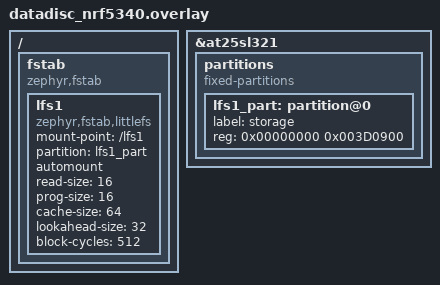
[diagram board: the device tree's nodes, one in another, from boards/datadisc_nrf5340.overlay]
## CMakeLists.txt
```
#
# Copyright (c) 2020-2022 Griffin Adams
#
# SPDX-License-Identifier: Apache-2.0
#

cmake_minimum_required(VERSION 3.20.4)

set(ZEPHYR_EXTRA_MODULES ${CMAKE_CURRENT_LIST_DIR}/drivers/kx134 ${CMAKE_CURRENT_LIST_DIR}/drivers/bm1422)
set(CONF_FILE ${CMAKE_CURRENT_LIST_DIR}/prj.conf)
list(APPEND CONF_FILE ${CMAKE_CURRENT_LIST_DIR}/kx134.conf)
list(APPEND CONF_FILE ${CMAKE_CURRENT_LIST_DIR}/bm1422.conf)
#set(DTC_OVERLAY_FILE ${CMAKE_CURRENT_LIST_DIR}/boards/datadisc_nrf5340_cpuapp.overlay)

find_package(Zephyr REQUIRED HINTS $ENV{ZEPHYR_BASE})
project(datadisc)

# Point to DataDisc root directory.
set(DATADISC_DIR ${CMAKE_CURRENT_LIST_DIR} CACHE PATH "DataDisc root directory")

FILE(GLOB app_sources src/*.c)
target_sources(app PRIVATE ${app_sources})

zephyr_library_include_directories(include)
```

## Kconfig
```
# Copyright (c) 2019-2020 Nordic Semiconductor ASA
# SPDX-License-Identifier: Apache-2.0

config APP_WIPE_STORAGE
	bool "Option to clear the flash area before mounting"
	help
	  Use this to force an existing file system to be created.

choice
	prompt "Storage and file system type used by the application"
	default APP_MSC_STORAGE_NONE
	help
	  Specify the type of storage and file system.

config APP_MSC_STORAGE_NONE
	bool "Use RAM disk as block device"
	imply DISK_DRIVER_RAM

config APP_MSC_STORAGE_RAM
	bool "Use RAM disk and FAT file system"
	imply DISK_DRIVER_RAM
	imply FILE_SYSTEM
	imply FAT_FILESYSTEM_ELM

config APP_MSC_STORAGE_FLASH_FATFS
	bool "Use FLASH disk and FAT file system"
	imply DISK_DRIVER_FLASH
	imply FILE_SYSTEM
	imply FAT_FILESYSTEM_ELM

config APP_MSC_STORAGE_FLASH_LITTLEFS
	bool "Use FLASH disk and LittleFS"
	imply DISK_DRIVER_FLASH
	imply FILE_SYSTEM
	imply FILE_SYSTEM_LITTLEFS

config APP_MSC_STORAGE_SDCARD
	bool "Use SDHC and FAT file system"
	imply DISK_DRIVER_SDMMC
	imply FILE_SYSTEM
	imply FAT_FILESYSTEM_ELM

endchoice

config DISK_RAM_VOLUME_SIZE
	default 32 if APP_MSC_STORAGE_NONE

config MASS_STORAGE_DISK_NAME
	default "NAND" if DISK_DRIVER_FLASH
	default "RAM" if DISK_DRIVER_RAM
	default "SD" if DISK_DRIVER_SDMMC

if DISK_DRIVER_FLASH

config FLASH_MAP
	default y

config FLASH_PAGE_LAYOUT
	default y

config DISK_FLASH_START
	default 0x0

config FLASH_LOG_LEVEL
	default 3

DT_COMPAT_QSPI_NOR := nordic,qspi-nor

config NORDIC_QSPI_NOR
	default $(dt_compat_enabled,$(DT_COMPAT_QSPI_NOR))

if NORDIC_QSPI_NOR

config NORDIC_QSPI_NOR_FLASH_LAYOUT_PAGE_SIZE
	default 4096

config DISK_FLASH_DEV_NAME
	default "MX25R64" if "$(dt_nodelabel_enabled,mx25r64)"
	default "GD25Q16" if "$(dt_nodelabel_enabled,gd25q16)"

config DISK_VOLUME_SIZE
	default 0x20000

config DISK_FLASH_MAX_RW_SIZE
	default 4096

config DISK_FLASH_ERASE_ALIGNMENT
	default 0x1000

config DISK_ERASE_BLOCK_SIZE
	default 0x1000

endif # NORDIC_QSPI_NOR

endif # DISK_DRIVER_FLASH

source "Kconfig.zephyr"
```

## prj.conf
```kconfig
# Enable mcumgr.
CONFIG_MCUMGR=y

# Enable most core commands.
CONFIG_MCUMGR_CMD_IMG_MGMT=y
CONFIG_MCUMGR_CMD_OS_MGMT=y

# Ensure an MCUboot-compatible binary is generated.
CONFIG_BOOTLOADER_MCUBOOT=y
CONFIG_PM_EXTERNAL_FLASH_MCUBOOT_SECONDARY=n

# enable console
CONFIG_USE_SEGGER_RTT=y
CONFIG_RTT_CONSOLE=y
CONFIG_UART_CONSOLE=n

# logging
CONFIG_LOG=y
CONFIG_LOG_PRINTK=y
CONFIG_LOG_BACKEND_RTT=y
CONFIG_LOG_DEFAULT_LEVEL=3
CONFIG_EXTRA_EXCEPTION_INFO=y

CONFIG_CPU_LOAD=y
CONFIG_CPU_LOAD_LOG_LEVEL_INF=y
CONFIG_CPU_LOAD_LOG_PERIODIC=y

# Enable the UART driver
CONFIG_UART_ASYNC_API=y
CONFIG_NRFX_UARTE0=y
CONFIG_SERIAL=y

# Bluetooth
CONFIG_BT=y
CONFIG_BT_SMP=y
CONFIG_BT_PERIPHERAL=y
CONFIG_BT_DEVICE_NAME="DataDisc v2"
CONFIG_BT_DEVICE_APPEARANCE=1345
CONFIG_BT_MAX_CONN=2
CONFIG_BT_MAX_PAIRED=2
CONFIG_BT_BAS=y

# Enable the NUS service
CONFIG_BT_NUS=y

# Allow for large Bluetooth data packets.
CONFIG_BT_L2CAP_TX_MTU=252
CONFIG_BT_BUF_ACL_RX_SIZE=256

# Enable the Bluetooth (unauthenticated) and shell mcumgr transports.
CONFIG_MCUMGR_SMP_BT=y
CONFIG_MCUMGR_SMP_BT_AUTHEN=n

# Some command handlers require a large stack.
CONFIG_SYSTEM_WORKQUEUE_STACK_SIZE=4092

# File System
# Optionally force the file system to be recreated
#CONFIG_APP_WIPE_STORAGE=y

# fs_dirent structures are big.
CONFIG_MAIN_STACK_SIZE=2048

# Let __ASSERT do its job
CONFIG_DEBUG=y

CONFIG_FLASH=y
CONFIG_FLASH_MAP=y
CONFIG_FLASH_PAGE_LAYOUT=y

# Nordic specific external flash stuff
#CONFIG_PM_EXTERNAL_FLASH=y
#CONFIG_PM_EXTERNAL_FLASH_DEV_NAME="AT25SL321"
CONFIG_PM_EXTERNAL_FLASH_BASE=0x0
#CONFIG_PM_EXTERNAL_FLASH_SIZE=0x00400000

CONFIG_FILE_SYSTEM=y
CONFIG_FAT_FILESYSTEM_ELM=y
#CONFIG_FS_FATFS_EXFAT=y

CONFIG_MPU_ALLOW_FLASH_WRITE=y

# USB related configs
CONFIG_USB_DEVICE_STACK=y
CONFIG_USB_DEVICE_PRODUCT="DataDisc"
CONFIG_USB_DRIVER_LOG_LEVEL_ERR=y
CONFIG_USB_MASS_STORAGE=y
CONFIG_USB_DEVICE_LOG_LEVEL_ERR=y
CONFIG_USB_MASS_STORAGE_LOG_LEVEL_ERR=y
#CONFIG_USB_CDC_ACM=y

CONFIG_APP_MSC_STORAGE_FLASH_FATFS=y

CONFIG_DISK_DRIVER_FLASH=y
CONFIG_DISK_FLASH_DEV_NAME="MX25U32"
#CONFIG_DISK_FLASH_DEV_NAME="AT25SL321"
CONFIG_DISK_VOLUME_SIZE=0x00400000


# Shell
CONFIG_PRINTK=y
#CONFIG_SHELL=y
#CONFIG_SHELL_MINIMAL=y
#CONFIG_SHELL_STACK_SIZE=1024
#CONFIG_SHELL_BACKEND_SERIAL=y

#CONFIG_THREAD_MONITOR=y
#CONFIG_INIT_STACKS=y
#CONFIG_BOOT_BANNER=n
#CONFIG_THREAD_NAME=y
#CONFIG_LOG=n
#CONFIG_CBPRINTF_NANO=y

#CONFIG_SHELL_BACKEND_SERIAL_CHECK_DTR=y
#CONFIG_UART_LINE_CTRL=y
#CONFIG_SHELL_BACKEND_SERIAL_INIT_PRIORITY=51

CONFIG_REBOOT=y

# Drivers
CONFIG_SENSOR=y

CONFIG_NFCT_PINS_AS_GPIOS=y

CONFIG_SPI=y
CONFIG_I2C=y
CONFIG_PWM=y
CONFIG_ADC=y

CONFIG_NEWLIB_LIBC=y

# Enable bonding
CONFIG_NVS=y
CONFIG_SETTINGS=y
CONFIG_BT_SETTINGS=n

CONFIG_ASSERT=y
```

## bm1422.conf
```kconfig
#
# bm1422 (C:/Users/Griffin/Desktop/Workspace/datadisc/drivers/bm1422)
#
CONFIG_BM1422=y
# CONFIG_BM1422_LOG_LEVEL_OFF is not set
# CONFIG_BM1422_LOG_LEVEL_ERR is not set
# CONFIG_BM1422_LOG_LEVEL_WRN is not set
CONFIG_BM1422_LOG_LEVEL_INF=y
# CONFIG_BM1422_LOG_LEVEL_DBG is not set
CONFIG_BM1422_12_BIT=y
# CONFIG_BM1422_14_BIT=y
# CONFIG_BM1422_AVC_NONE is not set
CONFIG_BM1422_AVC_2SAMPLES=y
# CONFIG_BM1422_AVC_4SAMPLES=y
# CONFIG_BM1422_AVC_8SAMPLES is not set
# CONFIG_BM1422_AVC_16SAMPLES is not set
# CONFIG_BM1422_ODR_10HZ is not set
# CONFIG_BM1422_ODR_20HZ is not set
# CONFIG_BM1422_ODR_100HZ=y
CONFIG_BM1422_ODR_1KHZ=y
CONFIG_BM1422_DREN=y
CONFIG_BM1422_DRP=y
# CONFIG_BM1422_TRIGGER_NONE is not set
# CONFIG_BM1422_TRIGGER_GLOBAL_THREAD is not set
CONFIG_BM1422_TRIGGER_OWN_THREAD=y
CONFIG_BM1422_THREAD_PRIORITY=10
CONFIG_BM1422_THREAD_STACK_SIZE=1024
# end of bm1422 (C:/Users/Griffin/Desktop/Workspace/datadisc/drivers/bm1422)
```

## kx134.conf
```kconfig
#
# kx134 (C:UsersGriffinDesktopWorkspacedatadiscdriverskx134)
#
CONFIG_KX134=y
# CONFIG_KX134_LOG_LEVEL_OFF is not set
# CONFIG_KX134_LOG_LEVEL_ERR is not set
# CONFIG_KX134_LOG_LEVEL_WRN is not set
CONFIG_KX134_LOG_LEVEL_INF=y
# CONFIG_KX134_LOG_LEVEL_DBG is not set
CONFIG_KX134_SPI=y
# CONFIG_KX134_LOW_POWER_MODE is not set
CONFIG_KX134_HIGH_PERF_MODE=y
# CONFIG_KX134_AVC_NONE is not set
# CONFIG_KX134_AVC_2SAMPLES is not set
CONFIG_KX134_AVC_4SAMPLES=y
# CONFIG_KX134_AVC_8SAMPLES is not set
# CONFIG_KX134_AVC_16SAMPLES=y
# CONFIG_KX134_AVC_32SAMPLES is not set
# CONFIG_KX134_AVC_64SAMPLES is not set
# CONFIG_KX134_AVC_128SAMPLES is not set
# CONFIG_KX134_RANGE_8G is not set
# CONFIG_KX134_RANGE_16G is not set
# CONFIG_KX134_RANGE_32G is not set
CONFIG_KX134_RANGE_64G=y
# CONFIG_KX134_C_MODE is not set
# CONFIG_KX134_PR_MODE is not set
# CONFIG_KX134_OSA_0HZ781 is not set
# CONFIG_KX134_OSA_1HZ563 is not set
# CONFIG_KX134_OSA_3HZ125 is not set
# CONFIG_KX134_OSA_6HZ25 is not set
# CONFIG_KX134_OSA_12HZ5 is not set
# CONFIG_KX134_OSA_25HZ is not set
# CONFIG_KX134_OSA_50HZ is not set
# CONFIG_KX134_OSA_100HZ=y
# CONFIG_KX134_OSA_200HZ is not set
CONFIG_KX134_OSA_400HZ=y
# CONFIG_KX134_OSA_800HZ=y
# CONFIG_KX134_OSA_1600HZ=y
# CONFIG_KX134_OSA_3200HZ is not set
# CONFIG_KX134_OSA_6400HZ is not set
# CONFIG_KX134_OSA_12800HZ is not set
# CONFIG_KX134_OSA_25600HZ is not set
# CONFIG_KX134_IIR_ODR_BY_9=y
CONFIG_KX134_IIR_ODR_BY_2=y
CONFIG_KX134_INT1=y
CONFIG_KX134_IEA1=y
# CONFIG_KX134_IEL1 is not set
# CONFIG_KX134_ACLR1 is not set
# CONFIG_KX134_FFI1 is not set
# CONFIG_KX134_BFI1 is not set
# CONFIG_KX134_WMI1 is not set
CONFIG_KX134_DRDYI1=y
# CONFIG_KX134_BTSI1 is not set
# CONFIG_KX134_TDTI1 is not set
# CONFIG_KX134_WUFI1 is not set
# CONFIG_KX134_TPI1 is not set
CONFIG_KX134_INT2=y
CONFIG_KX134_IEA2=y
# CONFIG_KX134_IEL2 is not set
# CONFIG_KX134_ACLR2 is not set
# CONFIG_KX134_FFI2 is not set
# CONFIG_KX134_BFI2 is not set
# CONFIG_KX134_WMI2 is not set
# CONFIG_KX134_DRDYI2 is not set
CONFIG_KX134_BTSI2=y
CONFIG_KX134_TDTI2=y
CONFIG_KX134_WUFI2=y
# CONFIG_KX134_TPI2 is not set
# CONFIG_KX134_AOI_OR is not set
CONFIG_KX134_AOI_AND=y

#
# Motion Interrupt Sources
#
CONFIG_KX134_XNWUE=y
CONFIG_KX134_XPWUE=y
CONFIG_KX134_YNWUE=y
CONFIG_KX134_YPWUE=y
CONFIG_KX134_ZNWUE=y
CONFIG_KX134_ZPWUE=y
# end of Motion Interrupt Sources

#
# Tap/Double-Tap Interrupt Sources
#
# CONFIG_KX134_TMEN is not set
# CONFIG_KX134_TLEM is not set
# CONFIG_KX134_TRIM is not set
# CONFIG_KX134_TDOM is not set
# CONFIG_KX134_TUPM is not set
CONFIG_KX134_TFDM=y
CONFIG_KX134_TFUM=y
# end of Tap/Double-Tap Interrupt Sources

CONFIG_KX134_OWUF_ODR_0HZ781=y
# CONFIG_KX134_OWUF_ODR_1HZ563 is not set
# CONFIG_KX134_OWUF_ODR_3HZ125 is not set
# CONFIG_KX134_OWUF_ODR_6HZ25 is not set
# CONFIG_KX134_OWUF_ODR_12HZ5 is not set
# CONFIG_KX134_OWUF_ODR_25HZ is not set
# CONFIG_KX134_OWUF_ODR_50HZ is not set
# CONFIG_KX134_OWUF_ODR_100HZ is not set
CONFIG_KX134_OBTS_ODR_0HZ781=y
# CONFIG_KX134_OBTS_ODR_1HZ563 is not set
# CONFIG_KX134_OBTS_ODR_3HZ125 is not set
# CONFIG_KX134_OBTS_ODR_6HZ25 is not set
# CONFIG_KX134_OBTS_ODR_12HZ5 is not set
# CONFIG_KX134_OBTS_ODR_25HZ is not set
# CONFIG_KX134_OBTS_ODR_50HZ is not set
# CONFIG_KX134_OBTS_ODR_100HZ is not set
CONFIG_KX134_TH_MODE=y
CONFIG_KX134_WUFTH=16
CONFIG_KX134_WUFC=0
CONFIG_KX134_BTSTH=8
CONFIG_KX134_BTSC=10
# CONFIG_KX134_OTDT_ODR_12HZ5 is not set
# CONFIG_KX134_OTDT_ODR_25HZ is not set
# CONFIG_KX134_OTDT_ODR_50HZ is not set
# CONFIG_KX134_OTDT_ODR_100HZ is not set
# CONFIG_KX134_OTDT_ODR_200HZ is not set
CONFIG_KX134_OTDT_ODR_400HZ=y
# CONFIG_KX134_OTDT_ODR_800HZ is not set
# CONFIG_KX134_OTDT_ODR_1600HZ is not set
CONFIG_KX134_DTRE=y
# CONFIG_KX134_STRE is not set
CONFIG_KX134_TDTC=108
CONFIG_KX134_TTH=51
CONFIG_KX134_TTL=25
CONFIG_KX134_FTD=162
CONFIG_KX134_STD=36
CONFIG_KX134_TLT=40
CONFIG_KX134_TWS=104
# CONFIG_KX134_ADPE is not set
# CONFIG_KX134_TRIGGER_NONE is not set
# CONFIG_KX134_TRIGGER_GLOBAL_THREAD is not set
CONFIG_KX134_TRIGGER_OWN_THREAD=y
CONFIG_KX134_THREAD_PRIORITY=10
CONFIG_KX134_THREAD_STACK_SIZE=1024
# end of kx134 (C:UsersGriffinDesktopWorkspacedatadiscdriverskx134)
```

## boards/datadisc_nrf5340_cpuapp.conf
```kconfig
#
# Copyright (c) 2022 Griffin Adams
#
# SPDX-License-Identifier: Apache-2.0
#
################################################################################
# Application overlay - DataDisc DFU
# CONFIG_MCUMGR=y
# CONFIG_MCUMGR=y
# CONFIG_MCUMGR_SMP_BT=y
# CONFIG_MCUMGR_SMP_BT_AUTHEN=n
# CONFIG_MCUMGR_SMP_BT_CONN_PARAM_CONTROL=y

# CONFIG_MCUMGR_CMD_IMG_MGMT=y
# CONFIG_MCUMGR_CMD_OS_MGMT=y

# Enable custom SMP request to erase settings partition.
# CONFIG_MCUMGR_GRP_ZEPHYR_BASIC=y
# CONFIG_MCUMGR_GRP_BASIC_CMD_STORAGE_ERASE=y

# Increase system workqueue stack size to prevent stack overflows while handling
# SMP requests.
CONFIG_SYSTEM_WORKQUEUE_STACK_SIZE=4096

CONFIG_BT_L2CAP_TX_MTU=498
CONFIG_BT_BUF_ACL_TX_SIZE=251
CONFIG_BT_BUF_ACL_RX_SIZE=502

# Use connection parameters that ensure quick data transfer
CONFIG_BT_PERIPHERAL_PREF_MIN_INT=6
CONFIG_BT_PERIPHERAL_PREF_MAX_INT=6
CONFIG_BT_PERIPHERAL_PREF_LATENCY=99
CONFIG_BT_PERIPHERAL_PREF_TIMEOUT=400

################################################################################
# Bootloader configuration

# CONFIG_BOOTLOADER_MCUBOOT=y
# CONFIG_MCUBOOT_IMAGE_VERSION="1.0.0+0"
# CONFIG_UPDATEABLE_IMAGE_NUMBER=2

# CONFIG_IMG_MANAGER=y
# CONFIG_MCUBOOT_IMG_MANAGER=y
# CONFIG_IMG_ERASE_PROGRESSIVELY=y

################################################################################
# External flash configuration

CONFIG_NORDIC_QSPI_NOR=y
CONFIG_NORDIC_QSPI_NOR_FLASH_LAYOUT_PAGE_SIZE=4096
CONFIG_NORDIC_QSPI_NOR_STACK_WRITE_BUFFER_SIZE=16

# FLASH nop device is enabled to prevent bus faults when mcumgr tries to access
# simulated partition with network core image data.
# CONFIG_FLASH_NOP_DEVICE=y

################################################################################
# Enable USB CDC ACM

CONFIG_USB_DEVICE_STACK=y
CONFIG_USB_DEVICE_REMOTE_WAKEUP=n
CONFIG_USB_DEVICE_PRODUCT="DataDisc"
CONFIG_USB_DEVICE_VID=0x1915
CONFIG_USB_DEVICE_PID=0x530E
CONFIG_USB_COMPOSITE_DEVICE=y
CONFIG_USB_CDC_ACM=y
CONFIG_USB_CDC_ACM_LOG_LEVEL_ERR=y
CONFIG_USB_DEVICE_LOG_LEVEL_ERR=y

#CONFIG_LOG_BACKEND_UART=y
CONFIG_LOG_PRINTK=y
CONFIG_LOG_PROCESS_THREAD_STACK_SIZE=1024
#CONFIG_LOG_PROCESS_THREAD_STARTUP_DELAY_MS=4000

# CONFIG_BT_NUS_UART_ASYNC_ADAPTER=y
# CONFIG_UART_INTERRUPT_DRIVEN=y

# Disable the UARTE0 enabled in default project configuration
# CONFIG_NRFX_UARTE0=n
# CONFIG_UART_NRFX=n
```

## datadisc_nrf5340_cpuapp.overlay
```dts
/*
 * Copyright (c) 2021 Griffin Adams
 *
 * SPDX-License-Identifier: Apache-2.0
 */
 
/delete-node/ &storage_partition;

&mx25u32 {
	partitions {
		compatible = "fixed-partitions";
		#address-cells = <1>;
		#size-cells = <1>;

		partition@0 {
			label = "storage";
			reg = <0x00000000 0x00400000>;
		};
	};
};
```

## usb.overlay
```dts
/*
 * Copyright (c) 2021 Nordic Semiconductor ASA
 *
 * SPDX-License-Identifier: LicenseRef-Nordic-5-Clause
 */

 / {
	chosen {
		zephyr,console = &cdc_acm_uart0;
		nordic,nus-uart = &cdc_acm_uart0;
	};
};

&zephyr_udc0 {
	cdc_acm_uart0: cdc_acm_uart0 {
		compatible = "zephyr,cdc-acm-uart";
		label = "CDC_ACM_0";
	};
};
```

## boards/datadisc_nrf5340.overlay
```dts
/*
 * Copyright (c) 2021 Griffin Adams
 *
 * SPDX-License-Identifier: Apache-2.0
 */

/delete-node/ &storage_partition;

/ {
	fstab {
		compatible = "zephyr,fstab";
		lfs1: lfs1 {
			compatible = "zephyr,fstab,littlefs";
			mount-point = "/lfs1";
			partition = <&lfs1_part>;
			automount;
			read-size = <16>;
			prog-size = <16>;
			cache-size = <64>;
			lookahead-size = <32>;
			block-cycles = <512>;
		};
	};
};

&at25sl321 {
	partitions {
		compatible = "fixed-partitions";
		#address-cells = <1>;
		#size-cells = <1>;

		lfs1_part: partition@0 {
			label = "storage";
			reg = <0x00000000 0x003D0900>;
		};
	};
};
```

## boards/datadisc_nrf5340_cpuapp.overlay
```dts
/*
 * Copyright (c) 2020 Nordic Semiconductor ASA
 *
 * SPDX-License-Identifier: Apache-2.0
 */

/delete-node/ &storage_partition;

&mx25u32 {
	partitions {
		compatible = "fixed-partitions";
		#address-cells = <1>;
		#size-cells = <1>;

		storage_partition: partition@0 {
			label = "storage";
			reg = <0x00000000 0x00040000>;
		};
	};
};
```

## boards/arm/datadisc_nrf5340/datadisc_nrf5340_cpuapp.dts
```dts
/*
 * Copyright (c) 2020-2022 Griffin Adams
 *
 * SPDX-License-Identifier: Apache-2.0
 */

/dts-v1/;
#include <nordic/nrf5340_cpuapp_qkaa.dtsi>
#include "nrf5340_cpuapp_common.dts"

/ {
	model = "DataDisc v2 NRF5340 Application";
	compatible = "nordic,datadisc-nrf5340-cpuapp";

	chosen {
		zephyr,sram = &sram0_image;
		zephyr,flash = &flash0;
		zephyr,code-partition = &slot0_partition;
		zephyr,sram-secure-partition = &sram0_s;
		zephyr,sram-non-secure-partition = &sram0_ns;
	};
};
```

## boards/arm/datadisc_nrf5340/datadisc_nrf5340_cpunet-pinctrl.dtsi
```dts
/*
 * Copyright (c) 2022 Nordic Semiconductor
 * SPDX-License-Identifier: Apache-2.0
 */

&pinctrl {
	// uart0_default: uart0_default {
	// 	group1 {
	// 		psels = <NRF_PSEL(UART_TX, 0, 24)>,
	// 			<NRF_PSEL(UART_RTS, 0, 23)>;
	// 	};
	// 	group2 {
	// 		psels = <NRF_PSEL(UART_RX, 0, 30)>,
	// 			<NRF_PSEL(UART_CTS, 0, 29)>;
	// 		bias-pull-up;
	// 	};
	// };

	// uart0_sleep: uart0_sleep {
	// 	group1 {
	// 		psels = <NRF_PSEL(UART_TX, 0, 24)>,
	// 			<NRF_PSEL(UART_RX, 0, 30)>,
	// 			<NRF_PSEL(UART_RTS, 0, 23)>,
	// 			<NRF_PSEL(UART_CTS, 0, 29)>;
	// 		low-power-enable;
	// 	};
	// };

};
```

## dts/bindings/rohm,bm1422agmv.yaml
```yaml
# Copyright (c) 2021 Griffin Adams
# SPDX-License-Identifier: Apache-2.0

description: BM1422AGMV 3-axis digital magnetometer, accessed through I2C bus

compatible: "rohm,bm1422agmv"

include: i2c-device.yaml

properties:
    irq-gpios:
      type: phandle-array
      required: false
      description: |
        The INT1 signal defaults to active high as produced by the
        sensor.  The property value should ensure the flags properly
        describe the signal that is presented to the driver.
```

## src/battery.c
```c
/*
 * Copyright (c) 2018-2019 Peter Bigot Consulting, LLC
 * Copyright (c) 2019-2020 Nordic Semiconductor ASA
 *
 * SPDX-License-Identifier: Apache-2.0
 */

#include <math.h>
#include <stdio.h>
#include <stdlib.h>

#include <zephyr/kernel.h>
#include <zephyr/init.h>
#include <zephyr/drivers/gpio.h>
#include <zephyr/drivers/adc.h>
#include <zephyr/drivers/sensor.h>
#include <zephyr/logging/log.h>

#include "battery.h"

LOG_MODULE_REGISTER(BATTERY, CONFIG_ADC_LOG_LEVEL);

#define VBATT DT_PATH(vbatt)
#define ZEPHYR_USER DT_PATH(zephyr_user)

#ifdef CONFIG_BOARD_THINGY52_NRF52832
/* This board uses a divider that reduces max voltage to
 * reference voltage (600 mV).
 */
#define BATTERY_ADC_GAIN ADC_GAIN_1
#else
/* Other boards may use dividers that only reduce battery voltage to
 * the maximum supported by the hardware (3.6 V)
 */
#define BATTERY_ADC_GAIN ADC_GAIN_1_6
#endif

struct io_channel_config {
	uint8_t channel;
};

struct divider_config {
	struct io_channel_config io_channel;
	struct gpio_dt_spec power_gpios;
	/* output_ohm is used as a flag value: if it is nonzero then
	 * the battery is measured through a voltage divider;
	 * otherwise it is assumed to be directly connected to Vdd.
	 */
	uint32_t output_ohm;
	uint32_t full_ohm;
};

static const struct divider_config divider_config = {
#if DT_NODE_HAS_STATUS(VBATT, okay)
	.io_channel = {
		DT_IO_CHANNELS_INPUT(VBATT),
	},
	.power_gpios = GPIO_DT_SPEC_GET_OR(VBATT, power_gpios, {}),
	.output_ohm = DT_PROP(VBATT, output_ohms),
	.full_ohm = DT_PROP(VBATT, full_ohms),
#else /* /vbatt exists */
	.io_channel = {
		DT_IO_CHANNELS_INPUT(ZEPHYR_USER),
	},
#endif /* /vbatt exists */
};

struct divider_data {
	const struct device *adc;
	struct adc_channel_cfg adc_cfg;
	struct adc_sequence adc_seq;
	int16_t raw;
};
static struct divider_data divider_data = {
#if DT_NODE_HAS_STATUS(VBATT, okay)
	.adc = DEVICE_DT_GET(DT_IO_CHANNELS_CTLR(VBATT)),
#else
	.adc = DEVICE_DT_GET(DT_IO_CHANNELS_CTLR(ZEPHYR_USER)),
#endif
};

static int divider_setup(void)
{
	const struct divider_config *cfg = &divider_config;
	const struct io_channel_config *iocp = &cfg->io_channel;
	const struct gpio_dt_spec *gcp = &cfg->power_gpios;
	struct divider_data *ddp = &divider_data;
	struct adc_sequence *asp = &ddp->adc_seq;
	struct adc_channel_cfg *accp = &ddp->adc_cfg;
	int rc;

	if (!device_is_ready(ddp->adc)) {
		LOG_ERR("ADC device is not ready %s", ddp->adc->name);
		return -ENOENT;
	}

	if (gcp->port) {
		if (!device_is_ready(gcp->port)) {
			LOG_ERR("%s: device not ready", gcp->port->name);
			return -ENOENT;
		}
		rc = gpio_pin_configure_dt(gcp, GPIO_OUTPUT_INACTIVE);
		if (rc != 0) {
			LOG_ERR("Failed to control feed %s.%u: %d",
				gcp->port->name, gcp->pin, rc);
			return rc;
		}
	}

	*asp = (struct adc_sequence){
		.channels = BIT(0),
		.buffer = &ddp->raw,
		.buffer_size = sizeof(ddp->raw),
		.oversampling = 4,
		.calibrate = true,
	};

#ifdef CONFIG_ADC_NRFX_SAADC
	*accp = (struct adc_channel_cfg){
		.gain = BATTERY_ADC_GAIN,
		.reference = ADC_REF_INTERNAL,
		.acquisition_time = ADC_ACQ_TIME(ADC_ACQ_TIME_MICROSECONDS, 40),
	};

	if (cfg->output_ohm != 0) {
		accp->input_positive = SAADC_CH_PSELP_PSELP_AnalogInput0
			+ iocp->channel;
	} else {
		accp->input_positive = SAADC_CH_PSELP_PSELP_VDD;
	}

	asp->resolution = 14;
#else /* CONFIG_ADC_var */
#error Unsupported ADC
#endif /* CONFIG_ADC_var */

	rc = adc_channel_setup(ddp->adc, accp);
	LOG_INF("Setup AIN%u got %d", iocp->channel, rc);

	return rc;
}

static bool battery_ok;

static int battery_setup(const struct device *arg)
{
	int rc = divider_setup();

	battery_ok = (rc == 0);
	LOG_INF("Battery setup: %d %d", rc, battery_ok);
	return rc;
}

SYS_INIT(battery_setup, APPLICATION, CONFIG_APPLICATION_INIT_PRIORITY);

int battery_measure_enable(bool enable)
{
	int rc = -ENOENT;

	if (battery_ok) {
		const struct gpio_dt_spec *gcp = &divider_config.power_gpios;

		rc = 0;
		if (gcp->port) {
			rc = gpio_pin_set_dt(gcp, enable);
		}
	}
	return rc;
}

int battery_sample(void)
{
	int rc = -ENOENT;

	if (battery_ok) {
		struct divider_data *ddp = &divider_data;
		const struct divider_config *dcp = &divider_config;
		struct adc_sequence *sp = &ddp->adc_seq;

		rc = adc_read(ddp->adc, sp);
		sp->calibrate = false;
		if (rc == 0) {
			int32_t val = ddp->raw;

			adc_raw_to_millivolts(adc_ref_internal(ddp->adc),
					      ddp->adc_cfg.gain,
					      sp->resolution,
					      &val);

			if (dcp->output_ohm != 0) {
				rc = val * (uint64_t)dcp->full_ohm
					/ dcp->output_ohm;
				LOG_DBG("raw %u ~ %u mV => %d mV\n",
					ddp->raw, val, rc);
			} else {
				rc = val;
				LOG_DBG("raw %u ~ %u mV\n", ddp->raw, val);
			}
		}
	}

	return rc;
}

unsigned int battery_level_pptt(unsigned int batt_mV,
				const struct battery_level_point *curve)
{
	const struct battery_level_point *pb = curve;

	if (batt_mV >= pb->lvl_mV) {
		/* Measured voltage above highest point, cap at maximum. */
		return pb->lvl_pptt;
	}
	/* Go down to the last point at or below the measured voltage. */
	while ((pb->lvl_pptt > 0)
	       && (batt_mV < pb->lvl_mV)) {
		++pb;
	}
	if (batt_mV < pb->lvl_mV) {
		/* Below lowest point, cap at minimum */
		return pb->lvl_pptt;
	}

	/* Linear interpolation between below and above points. */
	const struct battery_level_point *pa = pb - 1;

	return pb->lvl_pptt
	       + ((pa->lvl_pptt - pb->lvl_pptt)
		  * (batt_mV - pb->lvl_mV)
		  / (pa->lvl_mV - pb->lvl_mV));
}
```

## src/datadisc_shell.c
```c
/*
 * Copyright (c) 2022 Griffin Adams
 *
 * SPDX-License-Identifier: Apache-2.0
 */

#include <zephyr.h>
#include <shell/shell.h>
#include <version.h>
#include <logging/log.h>
#include <stdlib.h>
#include <ctype.h>

LOG_MODULE_REGISTER(datadisc_shell, CONFIG_LOG_DEFAULT_LEVEL);


static int cmd_log_test_start(const struct shell *shell, size_t argc,
			      char **argv, uint32_t period)
{
	ARG_UNUSED(argv);

	shell_print(shell, "Log test started\n");

	return 0;
}

static int cmd_log_test_start_demo(const struct shell *shell, size_t argc,
				   char **argv)
{
	return cmd_log_test_start(shell, argc, argv, 200);
}

static int cmd_log_test_start_flood(const struct shell *shell, size_t argc,
				    char **argv)
{
	return cmd_log_test_start(shell, argc, argv, 10);
}

static int cmd_log_test_stop(const struct shell *shell, size_t argc,
			     char **argv)
{
	ARG_UNUSED(argc);
	ARG_UNUSED(argv);

	shell_print(shell, "Log test stopped");

	return 0;
}

SHELL_STATIC_SUBCMD_SET_CREATE(sub_log_test_start,
	SHELL_CMD_ARG(demo, NULL,
		  "Start log timer which generates log message every 200ms.",
		  cmd_log_test_start_demo, 1, 0),
	SHELL_CMD_ARG(flood, NULL,
		  "Start log timer which generates log message every 10ms.",
		  cmd_log_test_start_flood, 1, 0),
	SHELL_SUBCMD_SET_END /* Array terminated. */
);
SHELL_STATIC_SUBCMD_SET_CREATE(sub_log_test,
	SHELL_CMD_ARG(start, &sub_log_test_start, "Start log test", NULL, 2, 0),
	SHELL_CMD_ARG(stop, NULL, "Stop log test.", cmd_log_test_stop, 1, 0),
	SHELL_SUBCMD_SET_END /* Array terminated. */
);

SHELL_CMD_REGISTER(log_test, &sub_log_test, "Log test", NULL);

static int cmd_demo_ping(const struct shell *shell, size_t argc, char **argv)
{
	ARG_UNUSED(argc);
	ARG_UNUSED(argv);

	shell_print(shell, "pong");

	return 0;
}

#if defined CONFIG_SHELL_GETOPT
static int cmd_demo_getopt(const struct shell *shell, size_t argc, char **argv)
{
	struct getopt_state *state;
	char *cvalue = NULL;
	int aflag = 0;
	int bflag = 0;
	int c;

	while ((c = shell_getopt(shell, argc, argv, "abhc:")) != -1) {
		state = shell_getopt_state_get(shell);
		switch (c) {
		case 'a':
			aflag = 1;
			break;
		case 'b':
			bflag = 1;
			break;
		case 'c':
			cvalue = state->optarg;
			break;
		case 'h':
			/* When getopt is active shell is not parsing
			 * command handler to print help message. It must
			 * be done explicitly.
			 */
			shell_help(shell);
			return SHELL_CMD_HELP_PRINTED;
		case '?':
			if (state->optopt == 'c') {
				shell_print(shell,
					"Option -%c requires an argument.",
					state->optopt);
			} else if (isprint(state->optopt)) {
				shell_print(shell,
					"Unknown option `-%c'.",
					state->optopt);
			} else {
				shell_print(shell,
					"Unknown option character `\\x%x'.",
					state->optopt);
			}
			return 1;
		default:
			break;
		}
	}

	shell_print(shell, "aflag = %d, bflag = %d", aflag, bflag);
	return 0;
}
#endif

static int cmd_demo_params(const struct shell *shell, size_t argc, char **argv)
{
	shell_print(shell, "argc = %d", argc);
	for (size_t cnt = 0; cnt < argc; cnt++) {
		shell_print(shell, "  argv[%d] = %s", cnt, argv[cnt]);
	}

	return 0;
}

static int cmd_demo_hexdump(const struct shell *shell, size_t argc, char **argv)
{
	shell_print(shell, "argc = %d", argc);
	for (size_t cnt = 0; cnt < argc; cnt++) {
		shell_print(shell, "argv[%d]", cnt);
		shell_hexdump(shell, argv[cnt], strlen(argv[cnt]));
	}

	return 0;
}

static int cmd_version(const struct shell *shell, size_t argc, char **argv)
{
	ARG_UNUSED(argc);
	ARG_UNUSED(argv);

	shell_print(shell, "Zephyr version %s", KERNEL_VERSION_STRING);

	return 0;
}

static int set_bypass(const struct shell *sh, shell_bypass_cb_t bypass)
{
	static bool in_use;

	if (bypass && in_use) {
		shell_error(sh, "Sample supports setting bypass on single instance.");

		return -EBUSY;
	}

	in_use = !in_use;
	if (in_use) {
		shell_print(sh, "Bypass started, press ctrl-x ctrl-q to escape");
		in_use = true;
	}

	shell_set_bypass(sh, bypass);

	return 0;
}

#define CHAR_1 0x18
#define CHAR_2 0x11

static void bypass_cb(const struct shell *sh, uint8_t *data, size_t len)
{
	static uint8_t tail;
	bool escape = false;

	/* Check if escape criteria is met. */
	if (tail == CHAR_1 && data[0] == CHAR_2) {
		escape = true;
	} else {
		for (int i = 0; i < (len - 1); i++) {
			if (data[i] == CHAR_1 && data[i + 1] == CHAR_2) {
				escape = true;
				break;
			}
		}
	}

	if (escape) {
		shell_print(sh, "Exit bypass");
		set_bypass(sh, NULL);
		tail = 0;
		return;
	}

	/* Store last byte for escape sequence detection */
	tail = data[len - 1];

	/* Do the data processing. */
	for (int i = 0; i < len; i++) {
		shell_fprintf(sh, SHELL_INFO, "%02x ", data[i]);
	}
	shell_fprintf(sh, SHELL_INFO, "| ");

	for (int i = 0; i < len; i++) {
		shell_fprintf(sh, SHELL_INFO, "%c", data[i]);
	}
	shell_fprintf(sh, SHELL_INFO, "\n");

}

static int cmd_bypass(const struct shell *sh, size_t argc, char **argv)
{
	return set_bypass(sh, bypass_cb);
}

static int cmd_dict(const struct shell *shell, size_t argc, char **argv,
		    void *data)
{
	int val = (intptr_t)data;

	shell_print(shell, "(syntax, value) : (%s, %d)", argv[0], val);

	return 0;
}

SHELL_SUBCMD_DICT_SET_CREATE(sub_dict_cmds, cmd_dict,
	(value_0, 0), (value_1, 1), (value_2, 2), (value_3, 3)
);

SHELL_STATIC_SUBCMD_SET_CREATE(sub_demo,
	SHELL_CMD(dictionary, &sub_dict_cmds, "Dictionary commands", NULL),
	SHELL_CMD(hexdump, NULL, "Hexdump params command.", cmd_demo_hexdump),
	SHELL_CMD(params, NULL, "Print params command.", cmd_demo_params),
	SHELL_CMD(ping, NULL, "Ping command.", cmd_demo_ping),
#if defined CONFIG_SHELL_GETOPT
	SHELL_CMD(getopt, NULL,	"Cammand using getopt, looking for: \"abhc:\".",
		  cmd_demo_getopt),
#endif
	SHELL_SUBCMD_SET_END /* Array terminated. */
);
SHELL_CMD_REGISTER(demo, &sub_demo, "Demo commands", NULL);

SHELL_CMD_ARG_REGISTER(version, NULL, "Show kernel version", cmd_version, 1, 0);

SHELL_CMD_ARG_REGISTER(bypass, NULL, "Bypass shell", cmd_bypass, 1, 0);
```

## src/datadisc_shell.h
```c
/*
 * Copyright (c) 2022 Griffin Adams
 *
 * SPDX-License-Identifier: Apache-2.0
 */

#ifndef DATADISC_SHELL_H_
#define DATADISC_SHELL_H_

/** Calculate the estimated battery level based on a measured voltage.
 *
 * @param batt_mV a measured battery voltage level.
 *
 * @param curve the discharge curve for the type of battery installed
 * on the system.
 *
 * @return the estimated remaining capacity in parts per ten
 * thousand.
 * TODO: change comment header above and add one for all functions
 */
static int cmd_log_test_start(const struct shell *shell, size_t argc,
			      char **argv, uint32_t period);

static int cmd_log_test_start_demo(const struct shell *shell, size_t argc,
				   char **argv);

static int cmd_log_test_start_flood(const struct shell *shell, size_t argc,
				    char **argv);

static int cmd_log_test_stop(const struct shell *shell, size_t argc,
			     char **argv);
static int cmd_demo_ping(const struct shell *shell, size_t argc, char **argv);

#if defined CONFIG_SHELL_GETOPT
static int cmd_demo_getopt(const struct shell *shell, size_t argc, char **argv);
#endif

static int cmd_demo_params(const struct shell *shell, size_t argc, char **argv);

static int cmd_demo_hexdump(const struct shell *shell, size_t argc, char **argv);

static int cmd_version(const struct shell *shell, size_t argc, char **argv);
static int cmd_bypass(const struct shell *sh, size_t argc, char **argv);
static int cmd_dict(const struct shell *shell, size_t argc, char **argv,
		    void *data);

#endif /* DATADISC_SHELL_H_ */
```
